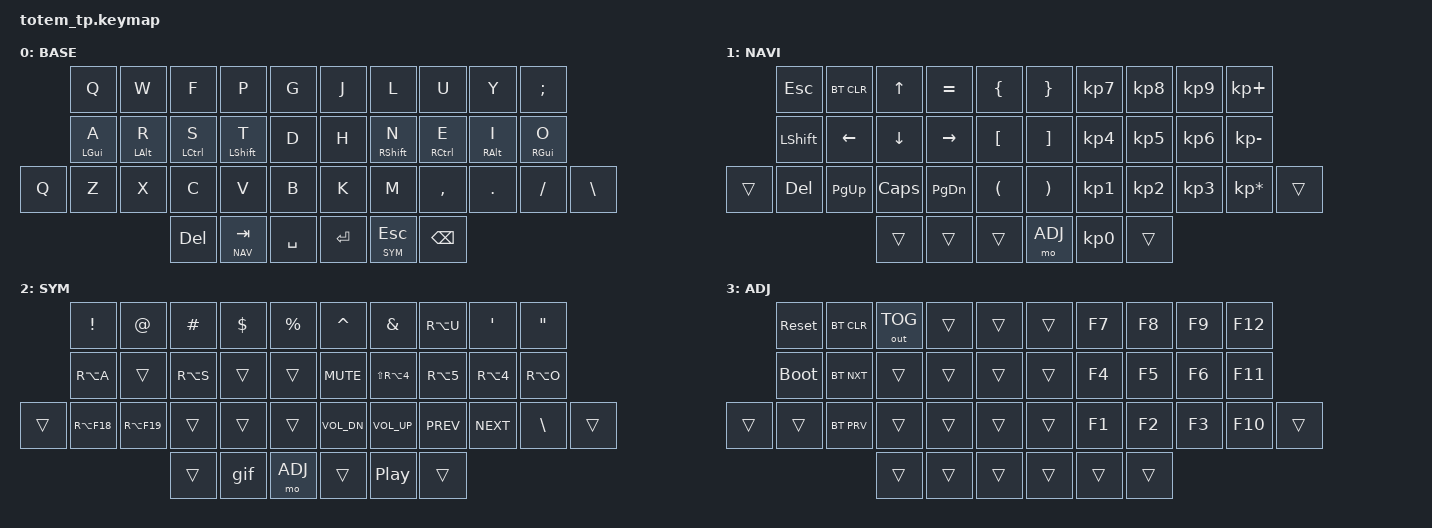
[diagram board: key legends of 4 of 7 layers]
//
//                                                        ▀▀▀▀▀     ▀▀▀▀▀          ▀▀█▀▀
//                                                        ▄▀▀▀▄  ▄  ▄▀▀▀▄  ▄  ▄▀▀▀▄  █  ▄▀▀▀▄
//                                                        █   █  █  █   █  █  █   █  █  █   █
//                                                         ▀▀▀   █   ▀▀▀   █   ▀▀▀   ▀   ▀▀▀
//                                                               █      ▄▄▄█▄▄▄    █   █  
//                                                               ▀      █  █  █     █▄█
//                                                             ▀▀▀▀▀    █  █  █      ▀
//                                                                      ▀  ▀  ▀
//
// ▄▄▄▄▄▄▄▄▄▄▄▄▄▄▄▄▄▄▄▄▄▄▄▄▄▄▄▄▄▄▄▄▄▄▄▄▄▄▄▄▄▄▄▄▄▄▄▄▄▄▄▄▄▄▄▄▄▄▄▄▄▄▄▄▄▄▄▄▄▄▄▄▄▄▄▄▄▄▄▄▄▄▄▄▄▄▄▄▄▄▄▄▄▄▄▄▄▄▄▄▄▄▄▄▄▄▄▄▄▄▄▄▄▄▄▄▄▄▄▄▄▄▄▄▄▄▄▄▄▄▄▄▄▄▄▄▄▄▄▄▄▄▄▄▄▄▄▄▄
       

#include <behaviors.dtsi>
#include <dt-bindings/zmk/keys.h>
#include <dt-bindings/zmk/bt.h>
#include <dt-bindings/zmk/outputs.h>

#define BASE 0
#define NAV  1
#define SYM  2
#define ADJ  3
#define MOUSE_KEYS 4
#define MOUSE_TP 5
#define MOUSE_TP_SET 6

#define HAS_MOUSE_KEYS
#define HAS_MOUSE_TP

#ifdef HAS_MOUSE_KEYS
  #include <dt-bindings/zmk/mouse.h>
  #include <behaviors/mouse_keys.dtsi>
#endif  // HAS_MOUSE_KEYS

#ifdef HAS_MOUSE_TP
  // We store the trackpoint settings in a separate file
  // to make organization a little easier.
  #include "include/mouse_tp.dtsi"
#endif  // HAS_MOUSE_TP


// Adjust layer keys based on enabled features.
//
// This prevents build errors when we build the firmware
// without the mouse keys PR or the TP module.
#ifdef HAS_MOUSE_KEYS
  #define U_THUMB_INNER &mo MOUSE_KEYS
#else
  #define U_THUMB_INNER &none
#endif  // HAS_MOUSE_KEYS

#ifdef HAS_MOUSE_TP
  #define U_TOG_TP_SET &tog MOUSE_TP_SET
#else
  #define U_TOG_TP_SET &none
#endif  // HAS_MOUSE_TP

&mt {
  quick-tap-ms = <100>;
  global-quick-tap;
  flavor = "tap-preferred";
  tapping-term-ms = <170>;
};

/ {
     combos {
            compatible = "zmk,combos";
            combo_esc {
                timeout-ms = <50>;
                key-positions = <0 1>;
                bindings = <&kp ESC>;
            };
    };

    macros {
        gif: gif {
            label = "giphy";
            compatible = "zmk,behavior-macro";
            #binding-cells = <0>;
            bindings
                = <&macro_press &kp LSHFT>
                , <&macro_tap &kp N2>
                , <&macro_release &kp LSHFT>
                , <&macro_tap &kp G &kp I &kp F>
                ;
        };
    };

        keymap {
                compatible = "zmk,keymap";
// ▄▄▄▄▄▄▄▄▄▄▄▄▄▄▄▄▄▄▄▄▄▄▄▄▄▄▄▄▄▄▄▄▄▄▄▄▄▄▄▄▄▄▄▄▄▄▄▄▄▄▄▄▄▄▄▄▄▄▄▄▄▄▄▄▄▄▄▄▄▄▄▄▄▄▄▄▄▄▄▄▄▄▄▄▄▄▄▄▄▄▄▄▄▄▄▄▄▄▄▄▄▄▄▄▄▄▄▄▄▄▄▄▄▄▄▄▄▄▄▄▄▄▄▄▄▄▄▄▄▄▄▄▄▄▄▄▄▄▄▄▄▄▄▄▄▄▄▄▄

                base_layer {
// ┏━━━━━━━━━━━━━━━━━━━━━━━━━━━━━━━━━━━━━━━┓
label= "BASE"                              ;
// ┗━━━━━━━━━━━━━━━━━━━━━━━━━━━━━━━━━━━━━━━┛
//             ┏━━━━━━━━━━━┳━━━━━━━━━━━┳━━━━━━━━━━━┳━━━━━━━━━━━┳━━━━━━━━━━━┓   ┏━━━━━━━━━━━┳━━━━━━━━━━━┳━━━━━━━━━━━┳━━━━━━━━━━━┳━━━━━━━━━━━┓
//             ┃     Q     ┃     W     ┃     F     ┃     P     ┃     G     ┃   ┃     J     ┃     L     ┃     U     ┃     Y     ┃     ;     ┃
//             ┣━━━━━━━━━━━╋━━━━━━━━━━━╋━━━━━━━━━━━╋━━━━━━━━━━━╋━━━━━━━━━━━┫   ┣━━━━━━━━━━━╋━━━━━━━━━━━╋━━━━━━━━━━━╋━━━━━━━━━━━╋━━━━━━━━━━━┫
//             ┃     A     ┃     R     ┃     S     ┃     T     ┃     D     ┃   ┃     H     ┃     N     ┃     E     ┃     I     ┃     O     ┃
// ┏━━━━━━━━━━━╋━━━━━━━━━━━╋━━━━━━━━━━━╋━━━━━━━━━━━╋━━━━━━━━━━━╋━━━━━━━━━━━┫   ┣━━━━━━━━━━━╋━━━━━━━━━━━╋━━━━━━━━━━━╋━━━━━━━━━━━╋━━━━━━━━━━━╋━━━━━━━━━━━┓
// ┃     Q     ┃     Z     ┃     X     ┃     C     ┃     V     ┃     B     ┃   ┃     K     ┃     M     ┃     ,     ┃     .     ┃     /     ┃     \     ┃
// ┗━━━━━━━━━━━┻━━━━━━━━━━━┻━━━━━━━━━━━╋━━━━━━━━━━━╋━━━━━━━━━━━╋━━━━━━━━━━━┫   ┣━━━━━━━━━━━╋━━━━━━━━━━━╋━━━━━━━━━━━╋━━━━━━━━━━━┻━━━━━━━━━━━┻━━━━━━━━━━━┛
//                                     ┃    DEL    ┃    TAB    ┃    SPC    ┃   ┃   ENTER   ┃           ┃   BSPC    ┃
//                                     ┗━━━━━━━━━━━┻━━━━━━━━━━━┻━━━━━━━━━━━┛   ┗━━━━━━━━━━━┻━━━━━━━━━━━┻━━━━━━━━━━━┛
 bindings = <
// ╷           ╷           ╷           ╷           ╷           ╷           ╷   ╷           ╷           ╷           ╷           ╷           ╷           ╷

                &kp Q       &kp W       &kp F       &kp P       &kp G           &kp J       &kp L       &kp U       &kp Y       &kp SEMI
                &mt LGUI A  &mt LALT R  &mt LCTRL S &mt LSHFT T &kp D           &kp H       &mt RSHFT N &mt RCTRL E &mt RALT I  &mt RGUI O
    &kp Q       &kp Z       &kp X       &kp C       &kp V       &kp B           &kp K       &kp M       &kp COMMA   &kp DOT     &kp FSLH    &kp BSLH
                                        &kp DEL   &lt NAV TAB   &kp SPACE       &kp RET   &lt SYM ESC   &kp BSPC
                        >;
                };

// ▄▄▄▄▄▄▄▄▄▄▄▄▄▄▄▄▄▄▄▄▄▄▄▄▄▄▄▄▄▄▄▄▄▄▄▄▄▄▄▄▄▄▄▄▄▄▄▄▄▄▄▄▄▄▄▄▄▄▄▄▄▄▄▄▄▄▄▄▄▄▄▄▄▄▄▄▄▄▄▄▄▄▄▄▄▄▄▄▄▄▄▄▄▄▄▄▄▄▄▄▄▄▄▄▄▄▄▄▄▄▄▄▄▄▄▄▄▄▄▄▄▄▄▄▄▄▄▄▄▄▄▄▄▄▄▄▄▄▄▄▄▄▄▄▄▄▄▄▄


                nav_layer {
// ┏━━━━━━━━━━━━━━━━━━━━━━━━━━━━━━━━━━━━━━━┓
label= "NAVI"                              ;
// ┗━━━━━━━━━━━━━━━━━━━━━━━━━━━━━━━━━━━━━━━┛
//             ┏━━━━━━━━━━━┳━━━━━━━━━━━┳━━━━━━━━━━━┳━━━━━━━━━━━┳━━━━━━━━━━━┓   ┏━━━━━━━━━━━┳━━━━━━━━━━━┳━━━━━━━━━━━┳━━━━━━━━━━━┳━━━━━━━━━━━┓
//             ┃           ┃           ┃     UP    ┃           ┃     {     ┃   ┃     }     ┃     7     ┃     8     ┃     9     ┃     +     ┃
//             ┣━━━━━━━━━━━╋━━━━━━━━━━━╋━━━━━━━━━━━╋━━━━━━━━━━━╋━━━━━━━━━━━┫   ┣━━━━━━━━━━━╋━━━━━━━━━━━╋━━━━━━━━━━━╋━━━━━━━━━━━╋━━━━━━━━━━━┫
//             ┃   SHIFT   ┃   LEFT    ┃    DOWN   ┃   RIGHT   ┃     [     ┃   ┃     ]     ┃     4     ┃     5     ┃     6     ┃     -     ┃
// ┏━━━━━━━━━━━╋━━━━━━━━━━━╋━━━━━━━━━━━╋━━━━━━━━━━━╋━━━━━━━━━━━╋━━━━━━━━━━━┫   ┣━━━━━━━━━━━╋━━━━━━━━━━━╋━━━━━━━━━━━╋━━━━━━━━━━━╋━━━━━━━━━━━╋━━━━━━━━━━━┓
// ┃           ┃           ┃   P UP    ┃  C LOCK   ┃  P DOWN   ┃     (     ┃   ┃     )     ┃     1     ┃     2     ┃     3     ┃     *     ┃           ┃
// ┗━━━━━━━━━━━┻━━━━━━━━━━━┻━━━━━━━━━━━╋━━━━━━━━━━━╋━━━━━━━━━━━╋━━━━━━━━━━━┫   ┣━━━━━━━━━━━╋━━━━━━━━━━━╋━━━━━━━━━━━╋━━━━━━━━━━━┻━━━━━━━━━━━┻━━━━━━━━━━━┛
//                                     ┃           ┃    TAB    ┃    SPC    ┃   ┃    DEL    ┃     0     ┃           ┃
//                                     ┗━━━━━━━━━━━┻━━━━━━━━━━━┻━━━━━━━━━━━┛   ┗━━━━━━━━━━━┻━━━━━━━━━━━┻━━━━━━━━━━━┛
 bindings = <
// ╷           ╷           ╷           ╷           ╷           ╷           ╷   ╷           ╷           ╷           ╷           ╷           ╷           ╷

                &kp ESC     &bt BT_CLR  &kp UP      &kp EQUAL   &kp LBRC        &kp RBRC    &kp KP_N7   &kp KP_N8   &kp KP_N9   &kp KP_PLUS
                &kp LSHFT   &kp LEFT    &kp DOWN    &kp RIGHT   &kp LBKT        &kp RBKT    &kp KP_N4   &kp KP_N5   &kp KP_N6   &kp KP_MINUS
    &trans      &kp DEL     &kp PG_UP   &kp CAPS    &kp PG_DN   &kp LPAR        &kp RPAR    &kp KP_N1   &kp KP_N2   &kp KP_N3   &kp KP_MULTIPLY &trans      
                                        &trans      &trans      &trans          &mo ADJ     &kp KP_N0   &trans      
                        >;
                };

// ▄▄▄▄▄▄▄▄▄▄▄▄▄▄▄▄▄▄▄▄▄▄▄▄▄▄▄▄▄▄▄▄▄▄▄▄▄▄▄▄▄▄▄▄▄▄▄▄▄▄▄▄▄▄▄▄▄▄▄▄▄▄▄▄▄▄▄▄▄▄▄▄▄▄▄▄▄▄▄▄▄▄▄▄▄▄▄▄▄▄▄▄▄▄▄▄▄▄▄▄▄▄▄▄▄▄▄▄▄▄▄▄▄▄▄▄▄▄▄▄▄▄▄▄▄▄▄▄▄▄▄▄▄▄▄▄▄▄▄▄▄▄▄▄▄▄▄▄▄


                sim_layer {
// ┏━━━━━━━━━━━━━━━━━━━━━━━━━━━━━━━━━━━━━━━┓
label= "SYM"                               ;
// ┗━━━━━━━━━━━━━━━━━━━━━━━━━━━━━━━━━━━━━━━┛
//             ┏━━━━━━━━━━━┳━━━━━━━━━━━┳━━━━━━━━━━━┳━━━━━━━━━━━┳━━━━━━━━━━━┓   ┏━━━━━━━━━━━┳━━━━━━━━━━━┳━━━━━━━━━━━┳━━━━━━━━━━━┳━━━━━━━━━━━┓
//             ┃     !     ┃     @     ┃     #     ┃     $     ┃     %     ┃   ┃     ˆ     ┃     &     ┃     Ü     ┃     '     ┃     "     ┃
//             ┣━━━━━━━━━━━╋━━━━━━━━━━━╋━━━━━━━━━━━╋━━━━━━━━━━━╋━━━━━━━━━━━┫   ┣━━━━━━━━━━━╋━━━━━━━━━━━╋━━━━━━━━━━━╋━━━━━━━━━━━╋━━━━━━━━━━━┫
//             ┃     Ä     ┃           ┃    SZ     ┃           ┃           ┃   ┃   MUTE    ┃   YEN     ┃   EURO    ┃  POUND    ┃     Ö     ┃
// ┏━━━━━━━━━━━╋━━━━━━━━━━━╋━━━━━━━━━━━╋━━━━━━━━━━━╋━━━━━━━━━━━╋━━━━━━━━━━━┫   ┣━━━━━━━━━━━╋━━━━━━━━━━━╋━━━━━━━━━━━╋━━━━━━━━━━━╋━━━━━━━━━━━╋━━━━━━━━━━━┓
// ┃           ┃  EMAIL1   ┃  EMAIL2   ┃           ┃           ┃           ┃   ┃   VOL-    ┃   VOL+    ┃   LAST    ┃   NEXT    ┃     \     ┃           ┃
// ┗━━━━━━━━━━━┻━━━━━━━━━━━┻━━━━━━━━━━━╋━━━━━━━━━━━╋━━━━━━━━━━━╋━━━━━━━━━━━┫   ┣━━━━━━━━━━━╋━━━━━━━━━━━╋━━━━━━━━━━━╋━━━━━━━━━━━┻━━━━━━━━━━━┻━━━━━━━━━━━┛
//                                     ┃           ┃    GIF    ┃    ADJ    ┃   ┃           ┃           ┃           ┃
//                                     ┗━━━━━━━━━━━┻━━━━━━━━━━━┻━━━━━━━━━━━┛   ┗━━━━━━━━━━━┻━━━━━━━━━━━┻━━━━━━━━━━━┛
 bindings = <
// ╷           ╷           ╷           ╷           ╷           ╷           ╷   ╷           ╷           ╷           ╷           ╷           ╷           ╷

                &kp EXCL    &kp AT      &kp HASH    &kp DLLR    &kp PRCNT       &kp CARET   &kp AMPS    &kp RA(U)   &kp SQT     &kp DQT       
                &kp RA(A)   &trans      &kp RA(S)   &trans      &trans          &kp C_MUTE  &kp LS(RA(N4)) &kp RA(N5) &kp RA(N4)   &kp RA(O) 
    &trans      &kp RA(F18) &kp RA(F19) &trans      &trans      &trans          &kp C_VOL_DN &kp C_VOL_UP &kp C_PREV &kp C_NEXT  &kp BSLH   &trans         
                                        &trans      &gif        &mo ADJ         &trans      &kp C_PP    &trans      
                        >;
                };

// ▄▄▄▄▄▄▄▄▄▄▄▄▄▄▄▄▄▄▄▄▄▄▄▄▄▄▄▄▄▄▄▄▄▄▄▄▄▄▄▄▄▄▄▄▄▄▄▄▄▄▄▄▄▄▄▄▄▄▄▄▄▄▄▄▄▄▄▄▄▄▄▄▄▄▄▄▄▄▄▄▄▄▄▄▄▄▄▄▄▄▄▄▄▄▄▄▄▄▄▄▄▄▄▄▄▄▄▄▄▄▄▄▄▄▄▄▄▄▄▄▄▄▄▄▄▄▄▄▄▄▄▄▄▄▄▄▄▄▄▄▄▄▄▄▄▄▄▄▄


                adjust_layer {
// ┏━━━━━━━━━━━━━━━━━━━━━━━━━━━━━━━━━━━━━━━┓
label= "ADJ"                               ;
// ┗━━━━━━━━━━━━━━━━━━━━━━━━━━━━━━━━━━━━━━━┛
//             ┏━━━━━━━━━━━┳━━━━━━━━━━━┳━━━━━━━━━━━┳━━━━━━━━━━━┳━━━━━━━━━━━┓   ┏━━━━━━━━━━━┳━━━━━━━━━━━┳━━━━━━━━━━━┳━━━━━━━━━━━┳━━━━━━━━━━━┓
//             ┃   RESET   ┃ BT CLEAR  ┃  OUT TOG  ┃           ┃           ┃   ┃           ┃    F7     ┃    F8     ┃    F9     ┃    F12    ┃
//             ┣━━━━━━━━━━━╋━━━━━━━━━━━╋━━━━━━━━━━━╋━━━━━━━━━━━╋━━━━━━━━━━━┫   ┣━━━━━━━━━━━╋━━━━━━━━━━━╋━━━━━━━━━━━╋━━━━━━━━━━━╋━━━━━━━━━━━┫
//             ┃ BOOTLOAD  ┃ BT NEXT   ┃           ┃           ┃           ┃   ┃           ┃    F4     ┃    F5     ┃    F6     ┃    F11    ┃
// ┏━━━━━━━━━━━╋━━━━━━━━━━━╋━━━━━━━━━━━╋━━━━━━━━━━━╋━━━━━━━━━━━╋━━━━━━━━━━━┫   ┣━━━━━━━━━━━╋━━━━━━━━━━━╋━━━━━━━━━━━╋━━━━━━━━━━━╋━━━━━━━━━━━╋━━━━━━━━━━━┓
// ┃           ┃           ┃ BT PREV   ┃           ┃           ┃           ┃   ┃           ┃    F1     ┃    F2     ┃    F3     ┃    F10    ┃           ┃
// ┗━━━━━━━━━━━┻━━━━━━━━━━━┻━━━━━━━━━━━╋━━━━━━━━━━━╋━━━━━━━━━━━╋━━━━━━━━━━━┫   ┣━━━━━━━━━━━╋━━━━━━━━━━━╋━━━━━━━━━━━╋━━━━━━━━━━━┻━━━━━━━━━━━┻━━━━━━━━━━━┛
//                                     ┃           ┃           ┃           ┃   ┃           ┃           ┃           ┃
//                                     ┗━━━━━━━━━━━┻━━━━━━━━━━━┻━━━━━━━━━━━┛   ┗━━━━━━━━━━━┻━━━━━━━━━━━┻━━━━━━━━━━━┛
 bindings = <
// ╷           ╷           ╷           ╷           ╷           ╷           ╷   ╷           ╷           ╷           ╷           ╷           ╷           ╷

                &sys_reset  &bt BT_CLR &out OUT_TOG &trans      &trans          &trans      &kp F7      &kp F8      &kp F9      &kp F12
                &bootloader &bt BT_NXT  &trans      &trans      &trans          &trans      &kp F4      &kp F5      &kp F6      &kp F11  
    &trans      &trans      &bt BT_PRV  &trans      &trans      &trans          &trans      &kp F1      &kp F2      &kp F3      &kp F10     &trans         
                                        &trans      &trans      &trans          &trans      &trans      &trans      
                        >;
                };

// ▄▄▄▄▄▄▄▄▄▄▄▄▄▄▄▄▄▄▄▄▄▄▄▄▄▄▄▄▄▄▄▄▄▄▄▄▄▄▄▄▄▄▄▄▄▄▄▄▄▄▄▄▄▄▄▄▄▄▄▄▄▄▄▄▄▄▄▄▄▄▄▄▄▄▄▄▄▄▄▄▄▄▄▄▄▄▄▄▄▄▄▄▄▄▄▄▄▄▄▄▄▄▄▄▄▄▄▄▄▄▄▄▄▄▄▄▄▄▄▄▄▄▄▄▄▄▄▄▄▄▄▄▄▄▄▄▄▄▄▄▄▄▄▄▄▄▄▄▄


                        
#ifdef HAS_MOUSE_KEYS

    MouseKeys_layer {
      display-name = "MouseKeys";
      bindings = <
// ╭────────────────────────┬────────────────────────┬────────────────────────┬────────────────────────┬────────────────────────┬────────────────────────╮    ╭────────────────────────┬────────────────────────┬────────────────────────┬────────────────────────┬────────────────────────┬────────────────────────╮
     U_TOG_TP_SET             U_TOG_TP_SET             &none                    &mmv MOVE_UP             &msc SCRL_UP             &none                         &none                    &msc SCRL_UP             &mmv MOVE_UP             &none                    U_TOG_TP_SET              U_TOG_TP_SET
// ├────────────────────────┼────────────────────────┼────────────────────────┼────────────────────────┼────────────────────────┼────────────────────────┤    ├────────────────────────┼────────────────────────┼────────────────────────┼────────────────────────┼────────────────────────┼────────────────────────┤
     &trans                   &none                    &mmv MOVE_LEFT           &mmv MOVE_DOWN           &mmv MOVE_RIGHT          &none                         &none                    &mmv MOVE_LEFT           &mmv MOVE_DOWN           &mmv MOVE_RIGHT          &none                     &trans
// ├────────────────────────┼────────────────────────┼────────────────────────┼────────────────────────┼────────────────────────┼────────────────────────┤    ├────────────────────────┼────────────────────────┼────────────────────────┼────────────────────────┼────────────────────────┼────────────────────────┤
     &trans                   &none                    &none                    &none                    &msc SCRL_DOWN           &none                         &none                    &msc SCRL_DOWN           &none                    &none                    &trans                    &trans
// ╰────────────────────────┴────────────────────────┴────────────────────────┴────────────────────────┼────────────────────────┼────────────────────────┤    ├────────────────────────┼────────────────────────┼────────────────────────┼────────────────────────┴────────────────────────┼────────────────────────╯
                                                                                &mkp MCLK                &mkp LCLK                &mkp RCLK                     &mkp MCLK                &mkp LCLK                &mkp RCLK
//                                                                            ╰────────────────────────┴────────────────────────┴────────────────────────╯    ╰────────────────────────┴────────────────────────┴────────────────────────╯
      >;
    };

#endif

#ifdef HAS_MOUSE_TP

    // Automatically activated when the mouse or trackpoint moves.
    // Configured in `include/mouse_tp.dtsi`.
    MouseTP_layer {
      display-name = "TP";
      bindings = <
// ╭────────────────────────┬────────────────────────┬────────────────────────┬────────────────────────┬────────────────────────┬────────────────────────╮    ╭────────────────────────┬────────────────────────┬────────────────────────┬────────────────────────┬────────────────────────┬────────────────────────╮
     U_TOG_TP_SET             U_TOG_TP_SET             &trans                   &trans                   &msc SCRL_UP             &trans                        &trans                   &trans                   &trans                   &trans                   U_TOG_TP_SET              U_TOG_TP_SET
// ├────────────────────────┼────────────────────────┼────────────────────────┼────────────────────────┼────────────────────────┼────────────────────────┤    ├────────────────────────┼────────────────────────┼────────────────────────┼────────────────────────┼────────────────────────┼────────────────────────┤
     &trans                   &trans                   &trans                   &trans                   &trans                   &trans                        &trans                   &trans                   &trans                   &trans                   &trans                    &trans
// ├────────────────────────┼────────────────────────┼────────────────────────┼────────────────────────┼────────────────────────┼────────────────────────┤    ├────────────────────────┼────────────────────────┼────────────────────────┼────────────────────────┼────────────────────────┼────────────────────────┤
     &trans                   &trans                   &trans                   &trans                   &msc SCRL_DOWN           &trans                        &trans                   &trans                   &trans                   &trans                   &trans                    &trans
// ╰────────────────────────┴────────────────────────┴────────────────────────┴────────────────────────┼────────────────────────┼────────────────────────┤    ├────────────────────────┼────────────────────────┼────────────────────────┼────────────────────────┴────────────────────────┼────────────────────────╯
                                                                                &mkp MCLK                &mkp LCLK                &mkp RCLK                     &mkp MCLK                &mkp LCLK                &mkp RCLK
//                                                                            ╰────────────────────────┴────────────────────────┴────────────────────────╯    ╰────────────────────────┴────────────────────────┴────────────────────────╯
      >;
    };

    // You can find the defines for the actual key press behaviors in `include/mouse_tp.dtsi`.
    MouseSettings_layer {
      display-name = "TP Set";
      bindings = <
// ╭────────────────────────┬────────────────────────┬────────────────────────┬────────────────────────┬────────────────────────┬────────────────────────╮    ╭────────────────────────┬────────────────────────┬────────────────────────┬────────────────────────┬────────────────────────┬────────────────────────╮
     U_TOG_TP_SET             U_TOG_TP_SET             &none                    U_MSS_TP_S_D             U_MSS_TP_S_I             U_MSS_TP_PT_I                 U_MSS_TP_PT_I            U_MSS_TP_S_D             U_MSS_TP_S_I             &none                    U_TOG_TP_SET              U_TOG_TP_SET
// ├────────────────────────┼────────────────────────┼────────────────────────┼────────────────────────┼────────────────────────┼────────────────────────┤    ├────────────────────────┼────────────────────────┼────────────────────────┼────────────────────────┼────────────────────────┼────────────────────────┤
     U_MSS_RESET              U_MSS_RESET              &none                    U_MSS_TP_NI_D            U_MSS_TP_NI_I            U_MSS_TP_PT_D                 U_MSS_TP_PT_D            U_MSS_TP_NI_D            U_MSS_TP_NI_I            &none                    U_MSS_RESET               U_MSS_RESET
// ├────────────────────────┼────────────────────────┼────────────────────────┼────────────────────────┼────────────────────────┼────────────────────────┤    ├────────────────────────┼────────────────────────┼────────────────────────┼────────────────────────┼────────────────────────┼────────────────────────┤
     U_MSS_LOG                U_MSS_LOG                &none                    U_MSS_TP_V6_D            U_MSS_TP_V6_I            &none                         &none                    U_MSS_TP_V6_D            U_MSS_TP_V6_I            &none                    U_MSS_LOG                 U_MSS_LOG
// ╰────────────────────────┴────────────────────────┴────────────────────────┴────────────────────────┼────────────────────────┼────────────────────────┤    ├────────────────────────┼────────────────────────┼────────────────────────┼────────────────────────┴────────────────────────┼────────────────────────╯
                                                                                &trans                   &mkp LCLK                &mkp RCLK                     &none                    &mkp LCLK                &mkp RCLK
//                                                                            ╰────────────────────────┴────────────────────────┴────────────────────────╯    ╰────────────────────────┴────────────────────────┴────────────────────────╯
      >;
    };
#endif
        };
};
